# SAM9X60D1G_SOM register map
Vendor: Microchip Technology; Series: SAM9X6; File version: 0
Registers are 32-bit, read-write, reset 0x0 unless marked. A register's access mark holds for its fields unless they carry their own. Offsets are from the block's base; [hi:lo] are bit positions; lines under a group give offsets from that group; {n}, {i} and the like mark numbered series; 'fields as' and 'values as' point back to an identical list.

## EMAC0 — Ethernet MAC 10/100
Base 0xF802C000; register names take the prefix EMAC_
Same registers: EMAC1 0xF8030000
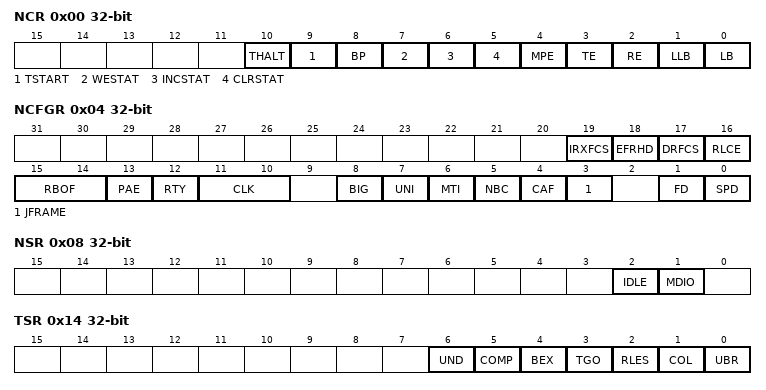
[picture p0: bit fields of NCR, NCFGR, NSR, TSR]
0x00 NCR — Network Control Register
  [10] THALT — Transmit Halt
  [9] TSTART — Start Transmission
  [8] BP — Back Pressure
  [7] WESTAT — Write Enable for Statistics Registers
  [6] INCSTAT — Increment Statistics Registers
  [5] CLRSTAT — Clear Statistics Registers
  [4] MPE — Management Port Enable
  [3] TE — Transmit Enable
  [2] RE — Receive Enable
  [1] LLB — Loopback Local
  [0] LB — LoopBack
0x04 NCFGR — Network Configuration Register
  [19] IRXFCS — Ignore RX FCS
  [18] EFRHD — Enable Frames Received in Half Duplex
  [17] DRFCS — Discard Receive FCS
  [16] RLCE — Receive Length Field Checking Enable
  [15:14] RBOF — Receive Buffer Offset
    0=OFFSET_0 (No offset from start of receive buffer); 1=OFFSET_1 (One-byte offset from start of receive buffer); 2=OFFSET_2 (Two-byte offset from start of receive buffer); 3=OFFSET_3 (Three-byte offset from start of receive buffer)
  [13] PAE — Pause Enable
  [12] RTY — Retry Test
  [11:10] CLK — MDC Clock Divider
    0=MCK_8 (MCK divided by 8 (MCK up to 20 MHz)); 1=MCK_16 (MCK divided by 16 (MCK up to 40 MHz)); 2=MCK_32 (MCK divided by 32 (MCK up to 80 MHz)); 3=MCK_64 (MCK divided by 64 (MCK up to 160 MHz))
  [8] BIG — Receive 1536 Bytes Frames
  [7] UNI — Unicast Hash Enable
  [6] MTI — Multicast Hash Enable
  [5] NBC — No Broadcast
  [4] CAF — Copy All Frames
  [3] JFRAME — Jumbo Frames
  [1] FD — Full Duplex
  [0] SPD — Speed
0x08 NSR ro — Network Status Register
  [2] IDLE — PHY Management Logic Status
  [1] MDIO — MDIO Input Status
0x14 TSR — Transmit Status Register
  [6] UND — Transmit Underrun (cleared by writing a one to this bit)
  [5] COMP — Transmit Complete (cleared by writing a one to this bit)
  [4] BEX — Buffers Exhausted Mid-frame (cleared by writing a one to this bit)
  [3] TGO — Transmit Go
  [2] RLES — Retry Limit Exceeded (cleared by writing a one to this bit)
  [1] COL — Collision Occurred (cleared by writing a one to this bit)
  [0] UBR — Used Bit Read (cleared by writing a one to this bit)
0x18 RBQP — Receive Buffer Queue Pointer Register
  [31:2] ADDR — Receive Buffer Queue Pointer Address
0x1C TBQP — Transmit Buffer Queue Pointer Register
  [31:2] ADDR — Transmit Buffer Queue Pointer Address
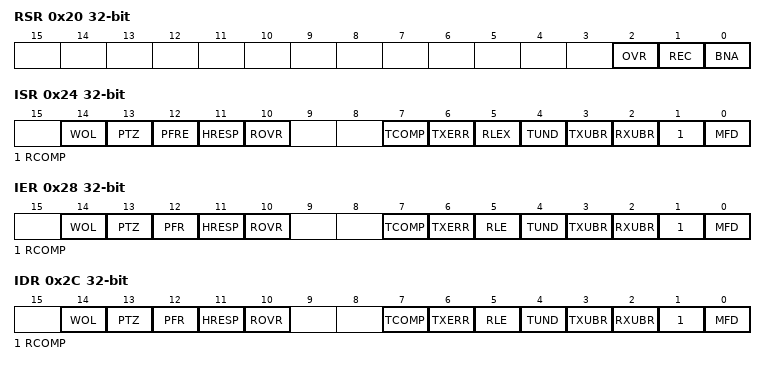
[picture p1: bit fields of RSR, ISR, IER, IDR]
0x20 RSR — Receive Status Register
  [2] OVR — Receive Overrun (cleared by writing a one to this bit)
  [1] REC — Frame Received (cleared by writing a one to this bit)
  [0] BNA — Buffer Not Available (cleared by writing a one to this bit)
0x24 ISR — Interrupt Status Register
  [14] WOL — Wake-On-LAN (cleared on read)
  [13] PTZ — Pause Time Zero (cleared on read)
  [12] PFRE — Pause Frame Received (cleared on read)
  [11] HRESP — Hresp Not OK (cleared on read)
  [10] ROVR — Receive Overrun (cleared on read)
  [7] TCOMP — Transmit Complete (cleared on read)
  [6] TXERR — Transmit Error (cleared on read)
  [5] RLEX — Retry Limit Exceeded (cleared on read)
  [4] TUND — Ethernet Transmit Buffer Underrun (cleared on read)
  [3] TXUBR — Transmit Used Bit Read (cleared on read)
  [2] RXUBR — Receive Used Bit Read (cleared on read)
  [1] RCOMP — Receive Complete (cleared on read)
  [0] MFD — Management Frame Done (cleared on read)
0x28 IER wo — Interrupt Enable Register
  [14] WOL — Wake-On-LAN
  [13] PTZ — Pause Time Zero
  [12] PFR — Pause Frame Received
  [11] HRESP — Hresp Not OK
  [10] ROVR — Receive Overrun
  [7] TCOMP — Transmit Complete
  [6] TXERR — Transmit Error
  [5] RLE — Retry Limit Exceeded
  [4] TUND — Ethernet Transmit Buffer Underrun
  [3] TXUBR — Transmit Used Bit Read
  [2] RXUBR — Receive Used Bit Read
  [1] RCOMP — Receive Complete
  [0] MFD — Management Frame Done
0x2C IDR wo — Interrupt Disable Register
  fields as IER
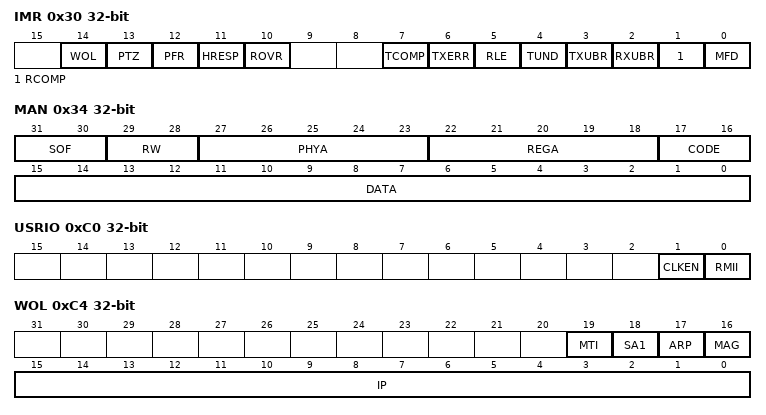
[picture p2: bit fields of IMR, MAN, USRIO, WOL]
0x30 IMR ro — Interrupt Mask Register
  fields as IER
0x34 MAN — PHY Maintenance Register
  [31:30] SOF — Start of Frame
  [29:28] RW — PHY Read/Write Command
  [27:23] PHYA — PHY Address
  [22:18] REGA — PHY Register Address
  [17:16] CODE — Must Be Two
  [15:0] DATA — PHY Transmit or Receive Data
0x38 PTR — Pause Time Register
  [15:0] PTIME — Pause Time
0x3C PFR — Pause Frames Received Register
  [15:0] FROK — Pause Frames Received OK
0x40 FTO — Frames Transmitted OK Register
  [23:0] FTOK — Frames Transmitted OK
0x44 SCF — Single Collision Frames Register
  [15:0] SCF — Single Collision Frames
0x48 MCF — Multiple Collision Frames Register
  [15:0] MCF — Multicollision Frames
0x4C FRO — Frames Received OK Register
  [23:0] FROK — Frames Received OK
0x50 FCSE — Frame Check Sequence Errors Register
  [7:0] FCSE — Frame Check Sequence Errors
0x54 ALE — Alignment Errors Register
  [7:0] ALE — Alignment Errors
0x58 DTF — Deferred Transmission Frames Register
  [15:0] DTF — Deferred Transmission Frames
0x5C LCOL — Late Collisions Register
  [7:0] LCOL — Late Collisions
0x60 ECOL — Excessive Collisions Register
  [7:0] EXCOL — Excessive Collisions
0x64 TUND — Transmit Underrun Errors Register
  [7:0] TUND — Transmit Underruns
0x68 CSE — Carrier Sense Errors Register
  [7:0] CSE — Carrier Sense Errors
0x6C RRE — Receive Resource Errors Register
  [15:0] RRE — Receive Resource Errors
0x70 ROV — Receive Overrun Errors Register
  [7:0] ROVR — Receive Overrun
0x74 RSE — Receive Symbol Errors Register
  [7:0] RSE — Receive Symbol Errors
0x78 ELE — Excessive Length Errors Register
  [7:0] EXL — Excessive Length Errors
0x7C RJA — Receive Jabbers Register
  [7:0] RJB — Receive Jabbers
0x80 USF — Undersize Frames Register
  [7:0] USF — Undersize Frames
0x84 STE — SQE Test Errors Register
  [7:0] SQER — SQE Test Errors
0x88 RLE — Received Length Field Mismatch Register
  [7:0] RLFM — Receive Length Field Mismatch
0x90 HRB — Hash Register Bottom [31:0] Register
  [31:0] ADDR — Hash Address Bottom
0x94 HRT — Hash Register Top [63:32] Register
  [31:0] ADDR — Hash Address Top
{0x98+8i} EMAC_SA[{i}] (i=0..3) group
  0x00 SAxB — Specific Address X Bottom Register
    [31:0] ADDR — Specific Address X Bottom
  0x04 SAxT — Specific Address X Top Register
    [15:0] ADDR — Specific Address X Top
0xB8 TID — Type ID Checking Register
  [15:0] TID — Type ID Checking
0xC0 USRIO — User Input/Output Register
  [1] CLKEN — Clock Enable
  [0] RMII — Reduced MII
0xC4 WOL — Wake-on-LAN Register
  [19] MTI — Multicast Hash Event Enable
  [18] SA1 — Specific Address Register 1 Event Enable
  [17] ARP — ARP Request Event Enable
  [16] MAG — Magic Packet Event Enable
  [15:0] IP — ARP Request IP Address

## Notices in the file
Copyright (c) 2026 Microchip Technology Inc.
SPDX-License-Identifier: Apache-2.0
Licensed under the Apache License, Version 2.0 (the "License");
you may not use this file except in compliance with the License.
You may obtain a copy of the License at
http://www.apache.org/licenses/LICENSE-2.0
Unless required by applicable law or agreed to in writing, software
distributed under the License is distributed on an "AS IS" BASIS,
WITHOUT WARRANTIES OR CONDITIONS OF ANY KIND, either express or implied.
See the License for the specific language governing permissions and
limitations under the License.
